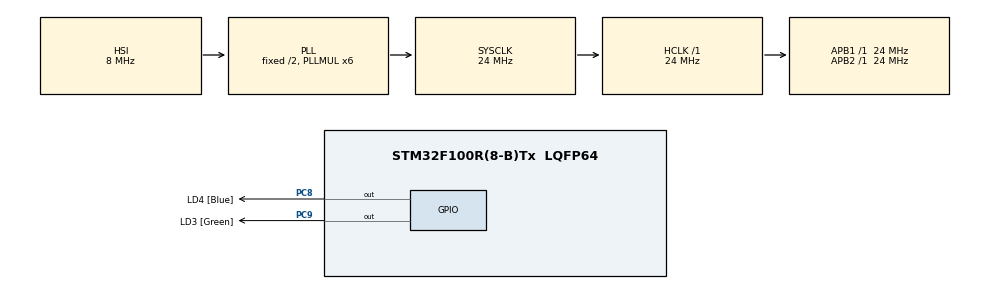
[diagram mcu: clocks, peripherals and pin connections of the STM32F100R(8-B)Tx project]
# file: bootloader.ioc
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Mcu.Family=STM32F1
Mcu.Name=STM32F100R(8-B)Tx
Mcu.Package=LQFP64
NVIC.PriorityGroup=NVIC_PRIORITYGROUP_4
NVIC.TIM7_IRQn=true\:0\:0\:false\:false\:true\:true\:true
PA0-WKUP.Mode=SYS_WakeUp0
PA0-WKUP.Signal=SYS_WKUP
PA13.GPIO_Label=TMS_SWDIO
PA13.Mode=Serial_Wire
PA13.Signal=SYS_JTMS-SWDIO
PA14.GPIO_Label=TCK_SWCLK
PA14.Mode=Serial_Wire
PA14.Signal=SYS_JTCK-SWCLK
PC14-OSC32_IN.Mode=LSE-External-Oscillator
PC14-OSC32_IN.Signal=RCC_OSC32_IN
PC15-OSC32_OUT.Mode=LSE-External-Oscillator
PC15-OSC32_OUT.Signal=RCC_OSC32_OUT
PC8.GPIO_Label=LD4 [Blue]
PC8.Signal=GPIO_Output
PC9.GPIO_Label=LD3 [Green]
PC9.Signal=GPIO_Output
PD0-OSC_IN.Mode=HSE-External-Oscillator
PD0-OSC_IN.Signal=RCC_OSC_IN
PD1-OSC_OUT.Mode=HSE-External-Oscillator
PD1-OSC_OUT.Signal=RCC_OSC_OUT
ProjectManager.HeapSize=0x200
ProjectManager.StackSize=0x400
ProjectManager.TargetToolchain=EWARM V8.32
RCC.AHBFreq_Value=24000000
RCC.APB1Freq_Value=24000000
RCC.APB1TimFreq_Value=24000000
RCC.APB2Freq_Value=24000000
RCC.APB2TimFreq_Value=24000000
RCC.HCLKFreq_Value=24000000
RCC.PLLMUL=RCC_PLL_MUL6
RCC.SYSCLKFreq_VALUE=24000000
RCC.SYSCLKSource=RCC_SYSCLKSOURCE_PLLCLK
TIM7.AutoReloadPreload=TIM_AUTORELOAD_PRELOAD_ENABLE
TIM7.Period=2449
TIM7.Prescaler=2449
TIM7.TIM_MasterOutputTrigger=TIM_TRGO_UPDATE
VP_TIM7_VS_ClockSourceINT.Mode=Enable_Timer
board=STM32VLDISCOVERY

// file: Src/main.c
/* USER CODE BEGIN Header */
/**
  ******************************************************************************
  * @file           : main.c
  * @brief          : Main program body
  ******************************************************************************
  * @attention
  *
  * <h2><center>&copy; Copyright (c) 2019 STMicroelectronics.
  * All rights reserved.</center></h2>
  *
  * This software component is licensed by ST under BSD 3-Clause license,
  * the "License"; You may not use this file except in compliance with the
  * License. You may obtain a copy of the License at:
  *                        opensource.org/licenses/BSD-3-Clause
  *
  ******************************************************************************
  */
/* USER CODE END Header */

#include "main.h"
#include "tim.h"
#include "gpio.h"

/* USER CODE BEGIN Includes */
#include "Bootloader_Extended.h"
/* USER CODE END Includes */

void SystemClock_Config(void);

int main(void)
{
  /* USER CODE BEGIN 1 */
  Vector_Init_Setting(BOOTLOADER_EXTENDED_START_ADDR);
  /* USER CODE END 1 */

  /* MCU Configuration--------------------------------------------------------*/

  /* Reset of all peripherals, Initializes the Flash interface and the Systick. */
  HAL_Init();

  /* Configure the system clock */
  SystemClock_Config();

  /* Initialize all configured peripherals */
  MX_GPIO_Init();
  MX_TIM7_Init();
  /* USER CODE BEGIN 2 */
//GPIOC->ODR ^= GPIO_ODR_ODR8;
//HAL_Delay(1500);
//GPIOC->ODR ^= GPIO_ODR_ODR8;
//HAL_Delay(1500);
//GPIOC->ODR ^= GPIO_ODR_ODR9;
//HAL_Delay(1500);
//GPIOC->ODR ^= GPIO_ODR_ODR9;
HAL_TIM_Base_Start_IT(&htim7);
HAL_Delay(15000);
Boot_Main_Program();
  /* USER CODE END 2 */

  /* Infinite loop */
  while (1)
  {

  }
}

void SystemClock_Config(void)
{
  RCC_OscInitTypeDef RCC_OscInitStruct = {0};
  RCC_ClkInitTypeDef RCC_ClkInitStruct = {0};

  /** Initializes the CPU, AHB and APB busses clocks
  */
  RCC_OscInitStruct.OscillatorType = RCC_OSCILLATORTYPE_HSI;
  RCC_OscInitStruct.HSIState = RCC_HSI_ON;
  RCC_OscInitStruct.HSICalibrationValue = RCC_HSICALIBRATION_DEFAULT;
  RCC_OscInitStruct.PLL.PLLState = RCC_PLL_ON;
  RCC_OscInitStruct.PLL.PLLSource = RCC_PLLSOURCE_HSI_DIV2;
  RCC_OscInitStruct.PLL.PLLMUL = RCC_PLL_MUL6;
  if (HAL_RCC_OscConfig(&RCC_OscInitStruct) != HAL_OK)
  {
    Error_Handler();
  }
  /** Initializes the CPU, AHB and APB busses clocks
  */
  RCC_ClkInitStruct.ClockType = RCC_CLOCKTYPE_HCLK|RCC_CLOCKTYPE_SYSCLK
                              |RCC_CLOCKTYPE_PCLK1|RCC_CLOCKTYPE_PCLK2;
  RCC_ClkInitStruct.SYSCLKSource = RCC_SYSCLKSOURCE_PLLCLK;
  RCC_ClkInitStruct.AHBCLKDivider = RCC_SYSCLK_DIV1;
  RCC_ClkInitStruct.APB1CLKDivider = RCC_HCLK_DIV1;
  RCC_ClkInitStruct.APB2CLKDivider = RCC_HCLK_DIV1;

  if (HAL_RCC_ClockConfig(&RCC_ClkInitStruct, FLASH_LATENCY_0) != HAL_OK)
  {
    Error_Handler();
  }
}

void Error_Handler(void)
{
}

/************************ (C) COPYRIGHT STMicroelectronics *****END OF FILE****/
